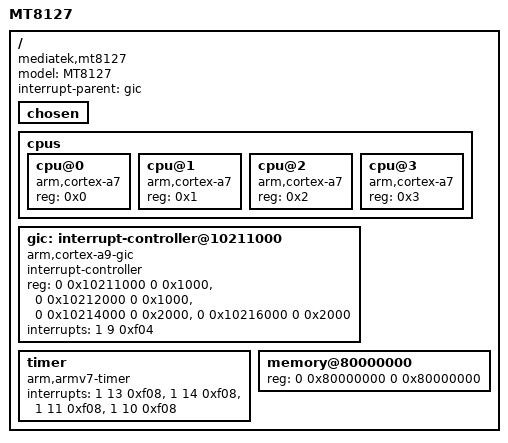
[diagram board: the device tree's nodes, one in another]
/*
 * MediaTek MT8127 P4V1
 *
 * Mediatek DTS
 */

/dts-v1/;

/memreserve/ 0xff000000 0x01000000;

/ {
	model = "MT8127";
	compatible = "mediatek,mt8127";
	interrupt-parent = <&gic>;
	#address-cells = <2>;
	#size-cells = <2>;

	chosen { };

	cpus {
		#address-cells = <1>;
		#size-cells = <0>;

		cpu@0 {
			device_type = "cpu";
			compatible = "arm,cortex-a7";
			reg = <0x0>;
		};
		cpu@1 {
			device_type = "cpu";
			compatible = "arm,cortex-a7";
			reg = <0x1>;
		};
		cpu@2 {
			device_type = "cpu";
			compatible = "arm,cortex-a7";
			reg = <0x2>;
		};
		cpu@3 {
			device_type = "cpu";
			compatible = "arm,cortex-a7";
			reg = <0x3>;
		};
	};

	gic: interrupt-controller@10211000 {
		compatible = "arm,cortex-a9-gic";
		#interrupt-cells = <3>;
		#address-cells = <0>;
		interrupt-controller;
		reg = <0 0x10211000 0 0x1000>,
		      <0 0x10212000 0 0x1000>,
		      <0 0x10214000 0 0x2000>,
		      <0 0x10216000 0 0x2000>;
		interrupts = <1 9 0xf04>;
	};

	timer {
		compatible = "arm,armv7-timer";
		interrupts = <1 13 0xf08>,
			     <1 14 0xf08>,
			     <1 11 0xf08>,
			     <1 10 0xf08>;
	};

	memory@80000000 {
		device_type = "memory";
		reg = <0 0x80000000 0 0x80000000>;
	};
};
